# LargeDummyDevice register map
File version: 1.0
Registers are 32-bit, read-write, no defined reset value unless marked. A register's access mark holds for its fields unless they carry their own. Offsets are from the block's base; [hi:lo] are bit positions.

## PERIPHERAL_93
Base 0x4005C000
0x04 REG_1 — Register 1
  [32:31] FIELD_3, [32:29] FIELD_7, [28] FIELD_17, [28:27] FIELD_1, [30:27] FIELD_8, [29:27] FIELD_9, [28:27] FIELD_14, [30:27] FIELD_15, [20:19] FIELD_18, [17:14] FIELD_11, [10] FIELD_5, [13:9] FIELD_12, [7] FIELD_4, [6] FIELD_10, [7:4] FIELD_13, [4:2] FIELD_6, [0] FIELD_2, [0] FIELD_16
0x08 REG_2 — Register 2
  [31:30] FIELD_9, [29] FIELD_21, [28] FIELD_1, [29:28] FIELD_5, [25] FIELD_3, [26:25] FIELD_8, [24:23] FIELD_17, [23:21] FIELD_18, [23:20] FIELD_13, [24:20] FIELD_14, [19:18] FIELD_2, [19:16] FIELD_11, [20:16] FIELD_16, [14] FIELD_6, [11:10] FIELD_12, [8:7] FIELD_7, [9:7] FIELD_20, [2:1] FIELD_10, [5:1] FIELD_15, [4:1] FIELD_19, [1:0] FIELD_4
0x0C REG_3 — Register 3
  [33:30] FIELD_3, [28:25] FIELD_1, [11] FIELD_5, [2:1] FIELD_4, [2:0] FIELD_2
0x10 REG_4 — Register 4
  [21] FIELD_2, [23:21] FIELD_13, [20:17] FIELD_9, [17:15] FIELD_4, [18:14] FIELD_6, [18:14] FIELD_8, [15:13] FIELD_15, [16:12] FIELD_14, [12:10] FIELD_7, [13:9] FIELD_1, [7] FIELD_5, [8:6] FIELD_17, [9:5] FIELD_12, [8:4] FIELD_16, [7:3] FIELD_11, [4:2] FIELD_3, [3:1] FIELD_10, [4:0] FIELD_18
0x14 REG_5 — Register 5
  [30:26] FIELD_9, [26:25] FIELD_13, [28:24] FIELD_14, [26:23] FIELD_2, [22:18] FIELD_7, [17] FIELD_1, [18:17] FIELD_6, [16:12] FIELD_5, [13:12] FIELD_11, [14:11] FIELD_10, [10:9] FIELD_12, [12:9] FIELD_15, [11:8] FIELD_8, [7] FIELD_4, [4] FIELD_3
0x18 REG_6 — Register 6
  [34:30] FIELD_3, [34:30] FIELD_19, [30] FIELD_28, [28:26] FIELD_6, [25] FIELD_9, [27:24] FIELD_16, [24] FIELD_18, [26:23] FIELD_23, [21:20] FIELD_29, [18:17] FIELD_11, [18:16] FIELD_26, [18:15] FIELD_1, [17:15] FIELD_15, [15:13] FIELD_5, [13] FIELD_17, [17:13] FIELD_31, [12] FIELD_8, [15:12] FIELD_10, [12] FIELD_20, [13:11] FIELD_25, [9] FIELD_2, [9] FIELD_22, [9:8] FIELD_4, [10:7] FIELD_12, [9:7] FIELD_14, [10:6] FIELD_30, [8:5] FIELD_13, [8:5] FIELD_21, [4] FIELD_7, [5:3] FIELD_27, [1:0] FIELD_24
0x1C REG_7 — Register 7
  [30] FIELD_19, [29:28] FIELD_7, [31:28] FIELD_12, [28:27] FIELD_11, [27:26] FIELD_2, [29:26] FIELD_13, [25] FIELD_9, [28:25] FIELD_10, [22:21] FIELD_14, [21] FIELD_20, [18] FIELD_4, [20:18] FIELD_16, [20:16] FIELD_1, [16:15] FIELD_18, [8:7] FIELD_23, [7:6] FIELD_21, [6:4] FIELD_24, [6:3] FIELD_17, [6:2] FIELD_6, [2] FIELD_15, [1:0] FIELD_3, [1:0] FIELD_5, [4:0] FIELD_8, [3:0] FIELD_22
0x20 REG_8 — Register 8
  [34:31] FIELD_13, [31:29] FIELD_3, [30:29] FIELD_19, [31:27] FIELD_1, [29:25] FIELD_9, [24:23] FIELD_6, [26:22] FIELD_8, [22] FIELD_15, [23:21] FIELD_18, [20] FIELD_17, [21:19] FIELD_5, [19:18] FIELD_16, [16] FIELD_4, [18:16] FIELD_12, [18:16] FIELD_20, [15] FIELD_7, [15:14] FIELD_2, [10:9] FIELD_11, [8:6] FIELD_10, [1] FIELD_14
0x24 REG_9 — Register 9
  [31] FIELD_3, [29] FIELD_17, [31:28] FIELD_8, [28:26] FIELD_9, [26:24] FIELD_21, [25:22] FIELD_2, [24:21] FIELD_4, [22:21] FIELD_18, [23:20] FIELD_19, [21:19] FIELD_13, [20:18] FIELD_10, [21:18] FIELD_12, [16:15] FIELD_14, [16:14] FIELD_5, [14:13] FIELD_1, [16:12] FIELD_6, [12] FIELD_11, [10] FIELD_16, [10:8] FIELD_7, [5:1] FIELD_20, [2:0] FIELD_15
0x28 REG_10 — Register 10
  [15] FIELD_1, [15] FIELD_2, [9:7] FIELD_3
0x2C REG_11 — Register 11
  [33:31] FIELD_15, [35:31] FIELD_28, [31:30] FIELD_27, [32:28] FIELD_26, [25:24] FIELD_7, [24] FIELD_13, [26:23] FIELD_18, [25:23] FIELD_20, [24:22] FIELD_14, [21] FIELD_4, [23:21] FIELD_8, [22:21] FIELD_9, [20] FIELD_17, [20:19] FIELD_16, [23:19] FIELD_29, [18] FIELD_11, [18:17] FIELD_1, [17] FIELD_23, [18:14] FIELD_24, [16:12] FIELD_31, [9] FIELD_3, [13:9] FIELD_21, [12:8] FIELD_10, [9:7] FIELD_2, [11:7] FIELD_19, [8:4] FIELD_6, [3] FIELD_12, [6:3] FIELD_30, [2] FIELD_5, [4:1] FIELD_22, [0] FIELD_25
0x30 REG_12 — Register 12
  [33:30] FIELD_13, [30] FIELD_17, [31:29] FIELD_12, [28] FIELD_8, [26] FIELD_3, [26] FIELD_19, [23] FIELD_10, [23:20] FIELD_4, [21:20] FIELD_14, [18] FIELD_6, [21:17] FIELD_11, [17:14] FIELD_7, [16:13] FIELD_1, [15:12] FIELD_20, [13:11] FIELD_18, [10] FIELD_2, [8:7] FIELD_16, [10:6] FIELD_15, [5:1] FIELD_5, [2:0] FIELD_9
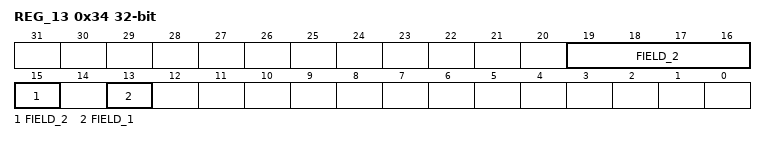
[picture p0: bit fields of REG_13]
0x34 REG_13 — Register 13
  [19:15] FIELD_2, [13] FIELD_1
0x38 REG_14 — Register 14
  [29:28] FIELD_2, [24] FIELD_8, [16] FIELD_6, [12:9] FIELD_5, [7:6] FIELD_7, [9:5] FIELD_1, [5] FIELD_3, [2:0] FIELD_4
0x3C REG_15 — Register 15
  [29] FIELD_20, [31:28] FIELD_11, [28:26] FIELD_16, [25] FIELD_7, [29:25] FIELD_12, [25:23] FIELD_10, [22] FIELD_26, [24:20] FIELD_18, [21:19] FIELD_21, [17:16] FIELD_17, [16:15] FIELD_2, [15:14] FIELD_3, [13] FIELD_15, [16:13] FIELD_23, [13:12] FIELD_8, [14:12] FIELD_25, [12:11] FIELD_19, [13:10] FIELD_1, [8:7] FIELD_14, [9:6] FIELD_6, [4] FIELD_4, [3:2] FIELD_13, [3:1] FIELD_5, [2:1] FIELD_9, [4:1] FIELD_22, [3:0] FIELD_24
0x40 REG_16 — Register 16
  [33:30] FIELD_20, [29] FIELD_12, [31:28] FIELD_21, [29:27] FIELD_6, [25] FIELD_22, [25:24] FIELD_24, [27:23] FIELD_14, [25:23] FIELD_16, [27:23] FIELD_26, [27:23] FIELD_28, [25:23] FIELD_29, [24:21] FIELD_3, [22:21] FIELD_13, [25:21] FIELD_19, [23:20] FIELD_11, [23:19] FIELD_5, [22:18] FIELD_17, [20:18] FIELD_23, [19:16] FIELD_9, [18:16] FIELD_30, [13:12] FIELD_1, [12] FIELD_8, [14:10] FIELD_7, [12:9] FIELD_10, [11:9] FIELD_18, [12:8] FIELD_25, [10:8] FIELD_27, [10:6] FIELD_2, [5] FIELD_4, [5] FIELD_15, [4:2] FIELD_31
0x44 REG_17 — Register 17
  [33:31] FIELD_5, [27:23] FIELD_8, [25:22] FIELD_3, [18] FIELD_10, [18:17] FIELD_4, [17:15] FIELD_1, [15:11] FIELD_7, [14:11] FIELD_9, [14:11] FIELD_12, [8] FIELD_2, [10:7] FIELD_11, [5:1] FIELD_6
0x48 REG_18 — Register 18
  [4:1] FIELD_1
0x4C REG_19 — Register 19
  [26:24] FIELD_1, [27:23] FIELD_6, [22] FIELD_5, [21] FIELD_7, [15:11] FIELD_3, [11:8] FIELD_2, [6:5] FIELD_4
0x50 REG_20 — Register 20
  [29:28] FIELD_5, [31:28] FIELD_8, [29:28] FIELD_12, [28:26] FIELD_9, [26] FIELD_20, [27:25] FIELD_15, [20] FIELD_19, [23:19] FIELD_3, [23:19] FIELD_21, [19:16] FIELD_1, [17:16] FIELD_2, [17:15] FIELD_10, [18:15] FIELD_13, [16:15] FIELD_16, [17:14] FIELD_14, [13:12] FIELD_22, [12:9] FIELD_18, [9:8] FIELD_11, [8:7] FIELD_7, [9:6] FIELD_6, [5:3] FIELD_4, [4:3] FIELD_23, [0] FIELD_17
0x54 REG_21 — Register 21
  [31] FIELD_5, [31] FIELD_11, [34:30] FIELD_9, [29] FIELD_7, [33:29] FIELD_17, [30:28] FIELD_14, [26] FIELD_6, [25:24] FIELD_15, [24:21] FIELD_12, [23:19] FIELD_2, [18] FIELD_8, [17] FIELD_10, [21:17] FIELD_20, [17:15] FIELD_21, [16:12] FIELD_19, [7:6] FIELD_16, [7:5] FIELD_4, [8:5] FIELD_13, [5:3] FIELD_18, [1] FIELD_1, [3:0] FIELD_3
0x58 REG_22 — Register 22
  [29:28] FIELD_7, [24:20] FIELD_5, [22:19] FIELD_1, [17:16] FIELD_10, [19:15] FIELD_8, [15:14] FIELD_3, [16:12] FIELD_2, [8:4] FIELD_4, [6:4] FIELD_6, [7:3] FIELD_9, [3] FIELD_11
0x5C REG_23 — Register 23
  [33:31] FIELD_21, [32:28] FIELD_4, [23] FIELD_6, [24:23] FIELD_7, [23:21] FIELD_19, [19:17] FIELD_18, [19:17] FIELD_23, [20:16] FIELD_8, [16] FIELD_9, [16:15] FIELD_11, [18:15] FIELD_12, [15] FIELD_17, [17:14] FIELD_10, [17:13] FIELD_3, [11:10] FIELD_1, [13:10] FIELD_24, [10:9] FIELD_20, [8] FIELD_16, [6] FIELD_2, [5] FIELD_14, [4:3] FIELD_13, [3] FIELD_22, [5:2] FIELD_5, [6:2] FIELD_15
0x60 REG_24 — Register 24
  [29:26] FIELD_5, [25] FIELD_4, [24] FIELD_2, [25:22] FIELD_1, [21] FIELD_6, [21] FIELD_9, [14:10] FIELD_7, [9:7] FIELD_10, [10:6] FIELD_8, [7:3] FIELD_3
0x64 REG_25 — Register 25
  [32:29] FIELD_18, [26:22] FIELD_7, [24:22] FIELD_13, [24:22] FIELD_15, [23:21] FIELD_12, [22:18] FIELD_11, [16:15] FIELD_9, [19:15] FIELD_14, [16:14] FIELD_10, [16:12] FIELD_1, [15:12] FIELD_2, [16:12] FIELD_6, [10] FIELD_5, [6:2] FIELD_16, [3:1] FIELD_4, [4:1] FIELD_8, [0] FIELD_3, [1:0] FIELD_17
0x68 REG_26 — Register 26
  [33:30] FIELD_7, [28] FIELD_6, [27:25] FIELD_10, [24:23] FIELD_8, [21:17] FIELD_3, [19:15] FIELD_11, [16:12] FIELD_5, [8] FIELD_2, [11:7] FIELD_1, [8:6] FIELD_9, [1] FIELD_4
0x6C REG_27 — Register 27
  [32:31] FIELD_1, [31:29] FIELD_3, [30:29] FIELD_5, [31:29] FIELD_10, [25:23] FIELD_8, [26:22] FIELD_4, [22:21] FIELD_13, [18:16] FIELD_6, [14] FIELD_15, [14:12] FIELD_2, [14:10] FIELD_11, [10:6] FIELD_14, [6:5] FIELD_7, [5:4] FIELD_9, [0] FIELD_12
0x70 REG_28 — Register 28
  [34:30] FIELD_8, [27] FIELD_6, [23] FIELD_7, [22] FIELD_9, [22:20] FIELD_4, [10] FIELD_1, [9:7] FIELD_2, [10:6] FIELD_5, [5] FIELD_10, [5:2] FIELD_3
0x74 REG_29 — Register 29
  [33:31] FIELD_10, [31] FIELD_11, [34:31] FIELD_19, [30:29] FIELD_2, [30:28] FIELD_20, [32:28] FIELD_24, [30:27] FIELD_7, [28:26] FIELD_25, [25:23] FIELD_4, [21:19] FIELD_8, [19:18] FIELD_13, [17:15] FIELD_16, [14] FIELD_22, [17:13] FIELD_1, [16:13] FIELD_29, [13:12] FIELD_12, [14:11] FIELD_14, [15:11] FIELD_26, [11:10] FIELD_6, [10] FIELD_28, [9] FIELD_3, [9] FIELD_17, [10:9] FIELD_30, [8] FIELD_27, [11:7] FIELD_23, [11:7] FIELD_31, [9:5] FIELD_5, [9:5] FIELD_9, [5] FIELD_21, [4] FIELD_15, [3:1] FIELD_18
0x78 REG_30 — Register 30
  [31:30] FIELD_11, [30:29] FIELD_2, [32:28] FIELD_1, [31:28] FIELD_3, [20] FIELD_7, [20:16] FIELD_9, [14:13] FIELD_6, [16:12] FIELD_10, [14:11] FIELD_5, [9:7] FIELD_8, [6] FIELD_4
0x7C REG_31 — Register 31
  [33:31] FIELD_12, [30] FIELD_4, [31:28] FIELD_19, [30:26] FIELD_6, [29:26] FIELD_14, [29:25] FIELD_11, [24] FIELD_15, [25:23] FIELD_3, [24:23] FIELD_9, [23:19] FIELD_5, [18:17] FIELD_10, [17:14] FIELD_7, [18:14] FIELD_17, [17:13] FIELD_2, [16:13] FIELD_13, [12] FIELD_16, [13:9] FIELD_18, [9:5] FIELD_1, [9:5] FIELD_8
0x80 REG_32 — Register 32
  [34:31] FIELD_15, [29:26] FIELD_11, [26:23] FIELD_6, [23:21] FIELD_4, [23:21] FIELD_9, [21:18] FIELD_7, [15:14] FIELD_10, [16:14] FIELD_12, [16:12] FIELD_17, [10] FIELD_1, [11:9] FIELD_5, [12:9] FIELD_14, [10:8] FIELD_2, [12:8] FIELD_16, [7:6] FIELD_18, [9:5] FIELD_13, [3:2] FIELD_8, [4:1] FIELD_3
0x84 REG_33 — Register 33
  [31:29] FIELD_4, [31:29] FIELD_20, [28] FIELD_28, [27] FIELD_3, [27:24] FIELD_7, [25:23] FIELD_11, [25:22] FIELD_10, [23:20] FIELD_1, [23:20] FIELD_23, [20:16] FIELD_9, [16] FIELD_19, [17:14] FIELD_13, [16:14] FIELD_27, [14:12] FIELD_14, [15:12] FIELD_25, [13:12] FIELD_26, [14:11] FIELD_17, [13:11] FIELD_21, [10] FIELD_6, [12:8] FIELD_5, [9:8] FIELD_24, [8:7] FIELD_15, [8:6] FIELD_12, [5:4] FIELD_2, [7:3] FIELD_8, [6:3] FIELD_16, [3:2] FIELD_18, [4:2] FIELD_22
0x88 REG_34 — Register 34
  [34:30] FIELD_1, [27:25] FIELD_2, [25:24] FIELD_12, [24:22] FIELD_6, [15:13] FIELD_5, [16:12] FIELD_10, [13:11] FIELD_11, [12:9] FIELD_7, [13:9] FIELD_8, [9:8] FIELD_4, [10:6] FIELD_9, [4:0] FIELD_3
0x8C REG_35 — Register 35
  [10:6] FIELD_1
0x90 REG_36 — Register 36
  [34:30] FIELD_5, [32:30] FIELD_9, [30:29] FIELD_12, [29:26] FIELD_6, [30:26] FIELD_21, [25] FIELD_2, [27:25] FIELD_23, [24] FIELD_13, [25:24] FIELD_25, [25:23] FIELD_22, [23:22] FIELD_15, [25:21] FIELD_10, [25:21] FIELD_31, [24:20] FIELD_1, [23:20] FIELD_7, [20:19] FIELD_27, [20:16] FIELD_4, [16:15] FIELD_14, [18:14] FIELD_20, [12] FIELD_26, [14:12] FIELD_30, [15:11] FIELD_24, [11:10] FIELD_17, [9] FIELD_3, [9] FIELD_8, [11:7] FIELD_19, [8:4] FIELD_11, [8:4] FIELD_16, [7:4] FIELD_28, [5:4] FIELD_29, [2:0] FIELD_18
0x94 REG_37 — Register 37
  [30] FIELD_7, [26:23] FIELD_8, [26:22] FIELD_6, [22:18] FIELD_2, [14:12] FIELD_5, [14:10] FIELD_3, [8:5] FIELD_4, [4:0] FIELD_1
0x98 REG_38 — Register 38
  [31:30] FIELD_6, [29:26] FIELD_4, [28:25] FIELD_8, [26:25] FIELD_11, [21:18] FIELD_2, [21:17] FIELD_5, [14:10] FIELD_3, [11:8] FIELD_1, [9:7] FIELD_7, [5:3] FIELD_10, [3:2] FIELD_9
0x9C REG_39 — Register 39
  [30] FIELD_2, [31:29] FIELD_5, [33:29] FIELD_21, [31:29] FIELD_25, [28:27] FIELD_6, [31:27] FIELD_9, [27:26] FIELD_3, [25:24] FIELD_10, [27:24] FIELD_16, [27:23] FIELD_7, [27:23] FIELD_18, [24:21] FIELD_24, [22:21] FIELD_27, [20:18] FIELD_17, [20:17] FIELD_4, [17:16] FIELD_11, [20:16] FIELD_19, [16:15] FIELD_12, [16:14] FIELD_13, [16:14] FIELD_23, [14] FIELD_26, [16:12] FIELD_20, [13:11] FIELD_14, [7:4] FIELD_15, [6:2] FIELD_1, [2] FIELD_8, [6:2] FIELD_22
0xA0 REG_40 — Register 40
  [33:31] FIELD_16, [26:25] FIELD_3, [22] FIELD_1, [22] FIELD_17, [21:17] FIELD_8, [17] FIELD_15, [18:16] FIELD_13, [15] FIELD_14, [16:14] FIELD_12, [17:13] FIELD_11, [9] FIELD_9, [8] FIELD_10, [8:7] FIELD_4, [9:7] FIELD_6, [10:6] FIELD_7, [6:4] FIELD_2, [3:2] FIELD_18, [4:0] FIELD_5
0xA4 REG_41 — Register 41
  [16:12] FIELD_3, [15:11] FIELD_2, [3] FIELD_1
0xA8 REG_42 — Register 42
  [33:29] FIELD_5, [29:28] FIELD_11, [29:27] FIELD_4, [29:26] FIELD_10, [29:26] FIELD_17, [24] FIELD_15, [24] FIELD_16, [22:20] FIELD_1, [18:17] FIELD_2, [15] FIELD_13, [18:15] FIELD_14, [14:12] FIELD_20, [14:11] FIELD_7, [11:9] FIELD_8, [13:9] FIELD_12, [10:7] FIELD_3, [7] FIELD_21, [8:7] FIELD_22, [6:5] FIELD_6, [7:5] FIELD_9, [4] FIELD_18, [2] FIELD_19
0xAC REG_43 — Register 43
  [24] FIELD_4, [28:24] FIELD_6, [24:23] FIELD_5, [23:22] FIELD_1, [11:7] FIELD_7, [7:5] FIELD_8, [7:3] FIELD_2, [5:1] FIELD_3
0xB0 REG_44 — Register 44
  [27] FIELD_4, [25:23] FIELD_1, [25:21] FIELD_5, [24:20] FIELD_3, [8:5] FIELD_7, [7:4] FIELD_2, [4:2] FIELD_6
0xB4 REG_45 — Register 45
  [25:21] FIELD_1, [9:5] FIELD_3, [6:2] FIELD_2
0xB8 REG_46 — Register 46
  [32:30] FIELD_13, [29] FIELD_1, [29] FIELD_11, [26:24] FIELD_17, [19:18] FIELD_10, [19:16] FIELD_6, [11] FIELD_2, [13:10] FIELD_3, [11:10] FIELD_7, [10:9] FIELD_19, [8] FIELD_8, [9:7] FIELD_12, [7:6] FIELD_18, [9:5] FIELD_16, [5:4] FIELD_20, [7:3] FIELD_4, [6:3] FIELD_15, [5:2] FIELD_9, [6:2] FIELD_14, [0] FIELD_5
0xBC REG_47 — Register 47
  [30] FIELD_21, [28:27] FIELD_20, [30:26] FIELD_6, [28:26] FIELD_8, [26] FIELD_10, [28:26] FIELD_22, [24] FIELD_1, [27:23] FIELD_18, [23] FIELD_25, [21] FIELD_4, [22:19] FIELD_15, [23:19] FIELD_23, [23:19] FIELD_24, [18:16] FIELD_11, [20:16] FIELD_14, [18:15] FIELD_7, [12:11] FIELD_13, [12:10] FIELD_5, [12:8] FIELD_12, [8] FIELD_17, [9:7] FIELD_2, [7:6] FIELD_9, [8:6] FIELD_19, [4:3] FIELD_16, [2] FIELD_3
